# CPU_TIPROP register map
Vendor: Texas Instruments
Peripheral module from a debugger description file (folder CC26x0R2F).
Registers are 32-bit, access per field, reset 0x0 unless marked. A register's access mark holds for its fields unless they carry their own. Offsets are as the file gives them; lines under a group give offsets from that group; [hi:lo] are bit positions; {n}, {i} and the like mark numbered series; 'fields as' and 'values as' point back to an identical list; <NAME> marks a mode.

## CPU_TIPROP — Cortex-M's TI proprietary registers
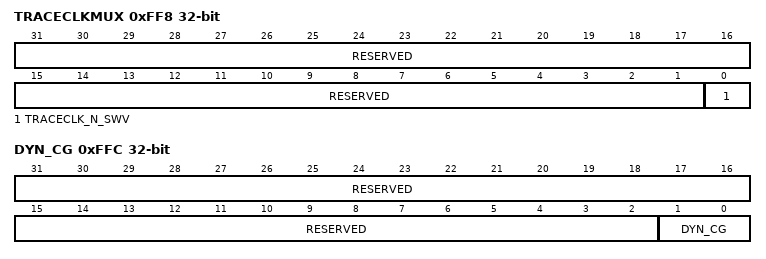
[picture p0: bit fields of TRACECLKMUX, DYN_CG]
0xFF8 TRACECLKMUX — Internal. Only to be used through TI provided API.
  [31:1] RESERVED ro — Internal. Only to be used through TI provided API.
  [0] TRACECLK_N_SWV rw — Internal. Only to be used through TI provided API.
    1=TRACECLK (Internal. Only to be used through TI provided API.); 0=SWV (Internal. Only to be used through TI provided API.)
0xFFC DYN_CG — Internal. Only to be used through TI provided API.
  [31:2] RESERVED ro — Internal. Only to be used through TI provided API.
  [1:0] DYN_CG rw — Internal. Only to be used through TI provided API.
